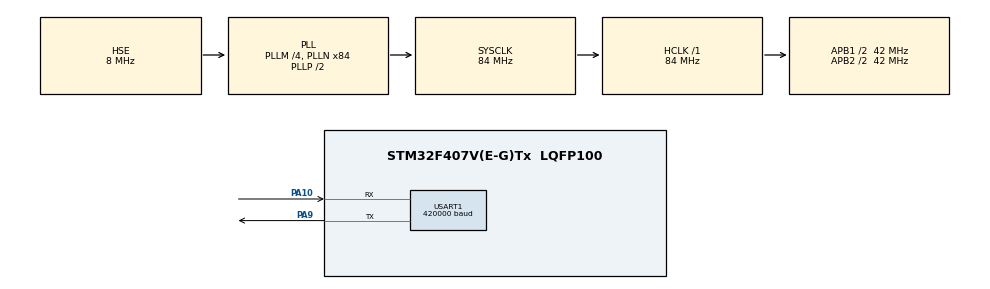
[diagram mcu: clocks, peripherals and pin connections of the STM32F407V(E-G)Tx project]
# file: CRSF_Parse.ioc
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Dma.Request0=USART1_RX
Dma.USART1_RX.0.Direction=DMA_PERIPH_TO_MEMORY
Dma.USART1_RX.0.FIFOMode=DMA_FIFOMODE_DISABLE
Dma.USART1_RX.0.Instance=DMA2_Stream2
Dma.USART1_RX.0.MemDataAlignment=DMA_MDATAALIGN_BYTE
Dma.USART1_RX.0.MemInc=DMA_MINC_ENABLE
Dma.USART1_RX.0.Mode=DMA_CIRCULAR
Dma.USART1_RX.0.PeriphDataAlignment=DMA_PDATAALIGN_BYTE
Dma.USART1_RX.0.PeriphInc=DMA_PINC_DISABLE
Dma.USART1_RX.0.Priority=DMA_PRIORITY_HIGH
Mcu.Family=STM32F4
Mcu.Name=STM32F407V(E-G)Tx
Mcu.Package=LQFP100
NVIC.DMA2_Stream2_IRQn=true\:0\:0\:false\:false\:true\:false\:true\:true
NVIC.PriorityGroup=NVIC_PRIORITYGROUP_4
PA10.Mode=Asynchronous
PA10.Signal=USART1_RX
PA9.Mode=Asynchronous
PA9.Signal=USART1_TX
PH0-OSC_IN.Mode=HSE-External-Oscillator
PH0-OSC_IN.Signal=RCC_OSC_IN
PH1-OSC_OUT.Mode=HSE-External-Oscillator
PH1-OSC_OUT.Signal=RCC_OSC_OUT
ProjectManager.HeapSize=0x200
ProjectManager.StackSize=0x400
ProjectManager.TargetToolchain=STM32CubeIDE
RCC.48MHZClocksFreq_Value=42000000
RCC.AHBFreq_Value=84000000
RCC.APB1CLKDivider=RCC_HCLK_DIV2
RCC.APB1Freq_Value=42000000
RCC.APB1TimFreq_Value=84000000
RCC.APB2CLKDivider=RCC_HCLK_DIV2
RCC.APB2Freq_Value=42000000
RCC.APB2TimFreq_Value=84000000
RCC.CortexFreq_Value=84000000
RCC.HCLKFreq_Value=84000000
RCC.HSE_VALUE=8000000
RCC.HSI_VALUE=16000000
RCC.LSE_VALUE=32768
RCC.PLLM=4
RCC.PLLN=84
RCC.PLLSourceVirtual=RCC_PLLSOURCE_HSE
RCC.SYSCLKFreq_VALUE=84000000
RCC.SYSCLKSource=RCC_SYSCLKSOURCE_PLLCLK
RCC.VCOOutputFreq_Value=168000000
USART1.BaudRate=420000
USART1.VirtualMode=VM_ASYNC
board=custom

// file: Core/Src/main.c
/* USER CODE BEGIN Header */
/**
  ******************************************************************************
  * @file           : main.c
  * @brief          : Main program body
  ******************************************************************************
  * @attention
  *
  * Copyright (c) 2025 STMicroelectronics.
  * All rights reserved.
  *
  * This software is licensed under terms that can be found in the LICENSE file
  * in the root directory of this software component.
  * If no LICENSE file comes with this software, it is provided AS-IS.
  *
  ******************************************************************************
  */
/* USER CODE END Header */
#include "main.h"

/* USER CODE BEGIN PD */
#define RX_BUFFER_SIZE 64
/* USER CODE END PD */

UART_HandleTypeDef huart1;
DMA_HandleTypeDef hdma_usart1_rx;

/* USER CODE BEGIN PV */
uint8_t rxBuffer[RX_BUFFER_SIZE]; // DMA buffer
uint8_t packetBuffer[RX_BUFFER_SIZE]; // Temporary buffer for packets
uint8_t packetIndex = 0; // Index for capturing packets
uint8_t expectedPacketLength = 0; // Expected full packet length

typedef struct {
	uint16_t values[16];
	uint32_t lastUpdateTime;
} RCChannels_t;

/* `rcChannels.values[<index>]` can be accessed to get the current
 * value of any channel at any given moment.
 * Example:
 * 		printf("%d\n", rcChannels.values[2]); // Print the value of 3rd channel
 */
static RCChannels_t rcChannels = {0};
/* USER CODE END PV */

void SystemClock_Config(void);
static void MX_GPIO_Init(void);
static void MX_DMA_Init(void);
static void MX_USART1_UART_Init(void);
/* USER CODE BEGIN PFP */
void parseCRSFPacket(uint8_t *packet, uint8_t length);
void parseRCChannels(uint8_t *payload);
/* USER CODE END PFP */

/* USER CODE BEGIN 0 */
void HAL_UART_RxCpltCallback(UART_HandleTypeDef *huart) {
	if (huart->Instance == USART1) {
		for (int i = 0; i < RX_BUFFER_SIZE; i++) {
			uint8_t byte = rxBuffer[i];

			if (packetIndex == 0) {
				if (byte == 0xC8) {  // Sync Byte
					packetBuffer[packetIndex++] = byte;
				}
			} else if (packetIndex == 1) {
				expectedPacketLength = byte + 2; // Total packet size
				packetBuffer[packetIndex++] = byte;

				if (expectedPacketLength > RX_BUFFER_SIZE) {
					packetIndex = 0;
				}
			} else {
				packetBuffer[packetIndex++] = byte;

				if (packetIndex == expectedPacketLength) {
					parseCRSFPacket(packetBuffer, packetIndex);
					packetIndex = 0;
				}
			}
		}

    HAL_UART_Receive_DMA(&huart1, rxBuffer, RX_BUFFER_SIZE);
	}
}

void HAL_UART_ErrorCallback(UART_HandleTypeDef *huart) {
	if (huart->Instance == USART1) {
		HAL_UART_Receive_DMA(&huart1, rxBuffer, RX_BUFFER_SIZE);
	}
}

void parseCRSFPacket(uint8_t *packet, uint8_t length) {
	// Invalid packet
	if (length < 3) return;

	uint8_t type = packet[2];  // Type index = 2
	uint8_t *payload = &packet[3];  // Payload index = 3

	switch (type) {
		case 0x16:  // RC Channels Data
			parseRCChannels(payload);
			break;
		default:
			break;
	}
}

void parseRCChannels(uint8_t *payload) {
	// Correct 11-bit extraction using bit shifts
	rcChannels.values[0]  = (payload[0]  | (payload[1]  << 8))  & 0x07FF;
	rcChannels.values[1]  = (payload[1]  >> 3 | (payload[2]  << 5))  & 0x07FF;
	rcChannels.values[2]  = (payload[2]  >> 6 | (payload[3]  << 2) | (payload[4]  << 10)) & 0x07FF;
	rcChannels.values[3]  = (payload[4]  >> 1 | (payload[5]  << 7))  & 0x07FF;
	rcChannels.values[4]  = (payload[5]  >> 4 | (payload[6]  << 4))  & 0x07FF;
	rcChannels.values[5]  = (payload[6]  >> 7 | (payload[7]  << 1) | (payload[8]  << 9)) & 0x07FF;
	rcChannels.values[6]  = (payload[8]  >> 2 | (payload[9]  << 6))  & 0x07FF;
	rcChannels.values[7]  = (payload[9]  >> 5 | (payload[10] << 3))  & 0x07FF;
	rcChannels.values[8]  = (payload[11] | (payload[12] << 8))  & 0x07FF;
	rcChannels.values[9]  = (payload[12] >> 3 | (payload[13] << 5))  & 0x07FF;
	rcChannels.values[10] = (payload[13] >> 6 | (payload[14] << 2) | (payload[15] << 10)) & 0x07FF;
	rcChannels.values[11] = (payload[15] >> 1 | (payload[16] << 7))  & 0x07FF;
	rcChannels.values[12] = (payload[16] >> 4 | (payload[17] << 4))  & 0x07FF;
	rcChannels.values[13] = (payload[17] >> 7 | (payload[18] << 1) | (payload[19] << 9)) & 0x07FF;
	rcChannels.values[14] = (payload[19] >> 2 | (payload[20] << 6))  & 0x07FF;
	rcChannels.values[15] = (payload[20] >> 5 | (payload[21] << 3))  & 0x07FF;

	rcChannels.lastUpdateTime = HAL_GetTick();
}
/* USER CODE END 0 */

int main(void)
{

  /* MCU Configuration--------------------------------------------------------*/

  /* Reset of all peripherals, Initializes the Flash interface and the Systick. */
  HAL_Init();

  /* Configure the system clock */
  SystemClock_Config();

  /* Initialize all configured peripherals */
  MX_GPIO_Init();
  MX_DMA_Init();
  MX_USART1_UART_Init();
  /* USER CODE BEGIN 2 */
  HAL_UART_Receive_DMA(&huart1, rxBuffer, RX_BUFFER_SIZE);
  /* USER CODE END 2 */

  /* Infinite loop */
  while (1)
  {

  }
}

void SystemClock_Config(void)
{
  RCC_OscInitTypeDef RCC_OscInitStruct = {0};
  RCC_ClkInitTypeDef RCC_ClkInitStruct = {0};

  /** Configure the main internal regulator output voltage
  */
  __HAL_RCC_PWR_CLK_ENABLE();
  __HAL_PWR_VOLTAGESCALING_CONFIG(PWR_REGULATOR_VOLTAGE_SCALE1);

  /** Initializes the RCC Oscillators according to the specified parameters
  * in the RCC_OscInitTypeDef structure.
  */
  RCC_OscInitStruct.OscillatorType = RCC_OSCILLATORTYPE_HSE;
  RCC_OscInitStruct.HSEState = RCC_HSE_ON;
  RCC_OscInitStruct.PLL.PLLState = RCC_PLL_ON;
  RCC_OscInitStruct.PLL.PLLSource = RCC_PLLSOURCE_HSE;
  RCC_OscInitStruct.PLL.PLLM = 4;
  RCC_OscInitStruct.PLL.PLLN = 84;
  RCC_OscInitStruct.PLL.PLLP = RCC_PLLP_DIV2;
  RCC_OscInitStruct.PLL.PLLQ = 4;
  if (HAL_RCC_OscConfig(&RCC_OscInitStruct) != HAL_OK)
  {
    Error_Handler();
  }

  /** Initializes the CPU, AHB and APB buses clocks
  */
  RCC_ClkInitStruct.ClockType = RCC_CLOCKTYPE_HCLK|RCC_CLOCKTYPE_SYSCLK
                              |RCC_CLOCKTYPE_PCLK1|RCC_CLOCKTYPE_PCLK2;
  RCC_ClkInitStruct.SYSCLKSource = RCC_SYSCLKSOURCE_PLLCLK;
  RCC_ClkInitStruct.AHBCLKDivider = RCC_SYSCLK_DIV1;
  RCC_ClkInitStruct.APB1CLKDivider = RCC_HCLK_DIV2;
  RCC_ClkInitStruct.APB2CLKDivider = RCC_HCLK_DIV2;

  if (HAL_RCC_ClockConfig(&RCC_ClkInitStruct, FLASH_LATENCY_2) != HAL_OK)
  {
    Error_Handler();
  }
}

static void MX_USART1_UART_Init(void)
{

  huart1.Instance = USART1;
  huart1.Init.BaudRate = 420000;
  huart1.Init.WordLength = UART_WORDLENGTH_8B;
  huart1.Init.StopBits = UART_STOPBITS_1;
  huart1.Init.Parity = UART_PARITY_NONE;
  huart1.Init.Mode = UART_MODE_TX_RX;
  huart1.Init.HwFlowCtl = UART_HWCONTROL_NONE;
  huart1.Init.OverSampling = UART_OVERSAMPLING_16;
  if (HAL_UART_Init(&huart1) != HAL_OK)
  {
    Error_Handler();
  }

}

static void MX_DMA_Init(void)
{

  /* DMA controller clock enable */
  __HAL_RCC_DMA2_CLK_ENABLE();

  /* DMA interrupt init */
  /* DMA2_Stream2_IRQn interrupt configuration */
  HAL_NVIC_SetPriority(DMA2_Stream2_IRQn, 0, 0);
  HAL_NVIC_EnableIRQ(DMA2_Stream2_IRQn);

}

static void MX_GPIO_Init(void)
{

  /* GPIO Ports Clock Enable */
  __HAL_RCC_GPIOH_CLK_ENABLE();
  __HAL_RCC_GPIOA_CLK_ENABLE();

}

void Error_Handler(void)
{
  __disable_irq();
  while (1)
  {
  }
}
